# apollo4b register map
Vendor: Ambiq Micro; Series: Apollo; File version: 1.0
CPU: CM4 r1p0, little endian, MPU, FPU, I-cache, D-cache, VTOR, ITCM, DTCM, 3 interrupt priority bits, 0 interrupts
Registers are 32-bit, read-write, reset 0x0 unless marked. A register's access mark holds for its fields unless they carry their own. Offsets are from the block's base; [hi:lo] are bit positions; {n}, {i} and the like mark numbered series; 'fields as' and 'values as' point back to an identical list.

## MCUCTRL — MCU Miscellaneous Control Logic
Base 0x40020000
0x00 CHIPPN reset 0x8320098 — Chip Information
  [31:0] PARTNUM — BCD part number.
    0x8000000=APOLLO4 (Apollo4 part number is 0x08xxxxxx.); 0x7000000=APOLLO3P (Apollo3P part number is 0x07xxxxxx.); 0x6000000=APOLLO3 (Apollo3 part number is 0x06xxxxxx.); 0x3000000=APOLLO2 (Apollo2 part number is 0x03xxxxxx.); 0x1000000=APOLLO (Apollo part number is 0x01xxxxxx.); 0xFF000000=PN_M (Mask for the part number field.); 24=PN_S (Bit position for the part number field.); 0xF00000=MRAMSIZE_M (Mask for the MRAM_SIZE field. Values: 0: 0.5MB 1: 1.0MB 2: 1.5MB 3: 2.0MB); 20=MRAMSIZE_S (Bit position for the MRAM_SIZE field.); 0xF0000=SRAMSIZE_M (Mask for the SRAM_SIZE field. Values: 0: 384KB+512KB 1: 384KB+1MB 2: 384KB+1MB+384KB+96KB); 16=SRAMSIZE_S (Bit position for the SRAM_SIZE field.); 0xFF00=REV_M (Mask for the revision field. Bits [15:12] are major rev, [11:8] are minor rev. Values: 0: Major Rev A, Minor Rev 0 1: Major Rev B, Minor Rev 1); 8=REV_S (Bit position for the revision field.); 192=PKG_M (Mask for the package field. Values: 0: SIP 1: QFN 2: BGA 3: CSP); 6=PKG_S (Bit position for the package field.); 56=PINS_M (Mask for the pins field. Values: 0: 25 pins 1: 49 pins 2: 64 pins 3: 81 pins); 3=PINS_S (Bit position for the pins field.); 1=TEMP_S (Bit position for the temperature field.)
0x04 CHIPID0 — Unique Chip ID 0
  [31:0] CHIPID0 — Unique chip ID 0.
0x08 CHIPID1 — Unique Chip ID 1
  [31:0] CHIPID1 — Unique chip ID 1.
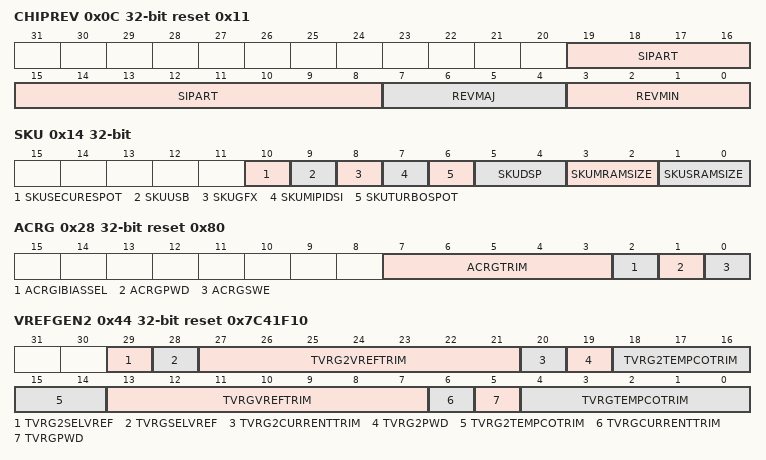
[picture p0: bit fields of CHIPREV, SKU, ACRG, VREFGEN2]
0x0C CHIPREV reset 0x11 — Chip Revision
  [19:8] SIPART — Silicon Part ID
  [7:4] REVMAJ — Major Revision ID.
    2=B (Apollo4 revision B); 1=A (Apollo4 revision A)
  [3:0] REVMIN — Minor Revision ID.
    3=REV2 (Apollo4 minor rev 2.); 2=REV1 (Apollo4 minor rev 1.); 1=REV0 (Apollo4 minor rev 0. Minor revision value, succeeding minor revisions will increment from this value.)
0x10 VENDORID — Unique Vendor ID
  [31:0] VENDORID
    0x414D4251=AMBIQ (Ambiq Vendor ID 'AMBQ')
0x14 SKU — Unique Chip SKU
  [10] SKUSECURESPOT — Secure boot feature
  [9] SKUUSB — USB available
  [8] SKUGFX — GFX available
  [7] SKUMIPIDSI — MIPI DSI available
  [6] SKUTURBOSPOT — High performance mode for MCU and DSPs.
  [5:4] SKUDSP — DSP availability SKU setting. 0:No DSPs available, 1: DSP0 only available, 2 (or 3): Both DSP0 and DSP1 are available
  [3:2] SKUMRAMSIZE — MRAM size SKU. 0:0.5MB, 1=1MB, 2=1.5MB, 3:2MB
  [1:0] SKUSRAMSIZE — SRAM SKU dictates the available memory for MCU. All of the MCU TCM is always available in addition to these. 0: 512K SSRAM, 1: 1MB SSRAM, 2: 1MB SSRAM + DSP Memories
0x20 DEBUGGER — Debugger Control
  [31:0] LOCKOUT — Lockout of debugger (SWD).
0x28 ACRG reset 0x80 — Active Current Reference Generator Control
  [7:3] ACRGTRIM — ACRG Trim value
  [2] ACRGIBIASSEL — Set the ACRG ibias. Note: the SWE mux select in PWRSEQ2SWE must be set for this to take effect. The inversion of this register is driven to analog.
    0=BGSEL (Selects the bandgap); 1=CCRGSEL (Selects the CCRG)
  [1] ACRGPWD — Power down the ACRG.
    1=ACRG_PWR_DN (Powers down the ACRG trim.)
  [0] ACRGSWE — Software enablement for ACRG register. A value of 1 will allow writes to the register
0x44 VREFGEN2 reset 0x7C41F10 — Voltage Reference Generator 2 Control
  [29] TVRG2SELVREF
  [28] TVRGSELVREF
  [27:21] TVRG2VREFTRIM — Calibrated voltage reference 580m trim
  [20] TVRG2CURRENTTRIM — Calibrated voltage reference current trim.
  [19] TVRG2PWD — Power Down, Calibrated Voltage Reference Generator.
    1=PWR_DN (Powers down the CVRG.)
  [18:14] TVRG2TEMPCOTRIM — Calibrated Voltage Reference Generator tc trim (bottom transistor)
  [13:7] TVRGVREFTRIM — Calibrated voltage reference 580m trim
  [6] TVRGCURRENTTRIM — Calibrated voltage reference current trim.
  [5] TVRGPWD — Power Down, Calibrated Voltage Reference Generator.
    1=PWR_DN (Powers down the CVRG.)
  [4:0] TVRGTEMPCOTRIM — Calibrated Voltage Reference Generator tc trim (bottom transistor)
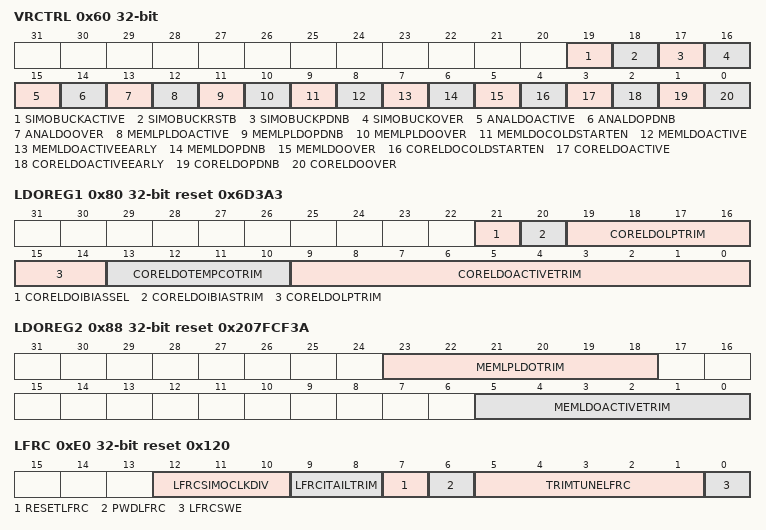
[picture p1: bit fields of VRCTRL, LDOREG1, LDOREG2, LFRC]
0x60 VRCTRL — Overrides for Voltage Regulators Controls
  [19] SIMOBUCKACTIVE — SIMO BUCK ACTIVE control. Override for PWRCTRL going to analog when SIMOBUCKOVER = 1
  [18] SIMOBUCKRSTB — SIMO BUCK RSTB control. Override for PWRCTRL going to analog when SIMOBUCKOVER = 1
  [17] SIMOBUCKPDNB — SIMO BUCK PDNB control. Override for PWRCTRL going to analog when SIMOBUCKOVER = 1
  [16] SIMOBUCKOVER — Override control for SIMO BUCK signals
  [15] ANALDOACTIVE — ANALDO LDO ACTIVE control. Override for PWRCTRL going to analog when ANALDOOVER = 1
  [14] ANALDOPDNB — ANALDO PDNB control. Override for PWRCTRL going to analog when ANALDOOVER = 1
  [13] ANALDOOVER — Override control for ANALDO signals
  [12] MEMLPLDOACTIVE — MEM LP LDO ACTVIVE control. Override for PWRCTRL going to analog when MEMLPLDOOVER = 1
  [11] MEMLPLDOPDNB — MEM LP LDO PDNB control. Override for PWRCTRL going to analog when MEMLPLDOOVER = 1
  [10] MEMLPLDOOVER — Override control for MEM LP LDO signals
  [9] MEMLDOCOLDSTARTEN — MEM LDO COLDSTART EN control. This is a shadow backed register and no need to set MEMLDOOVER.
  [8] MEMLDOACTIVE — MEM LDO ACTIVE control. Override for PWRCTRL going to analog when MEMLDOOVER = 1
  [7] MEMLDOACTIVEEARLY — MEM LDO EARLY ACTIVE control. Override for PWRCTRL going to analog when MEMLDOOVER = 1
  [6] MEMLDOPDNB — MEM LDO PDNB control. Override signal for PWRCTRL going to analog when MEMLDOOVER = 1
  [5] MEMLDOOVER — Override control for MEM LDO signals
  [4] CORELDOCOLDSTARTEN — CORE LDO COLDSTART EN control. This is a shadow backed register and no need to set CORELDOOVER.
  [3] CORELDOACTIVE — CORE LDO ACTIVE control. Override for PWRCTRL going to analog when CORELDOOVER = 1
  [2] CORELDOACTIVEEARLY — CORE LDO EARLY ACTIVE control. Override for PWRCTRL going to analog when CORELDOOVER = 1
  [1] CORELDOPDNB — CORE LDO PDNB control. Override for PWRCTRL going to analog when CORELDOOVER = 1
  [0] CORELDOOVER — Override control for CORE LDO signals
0x80 LDOREG1 reset 0x6D3A3 — CORELDO trims Reg
  [21] CORELDOIBIASSEL — Core LDO IBIAS sel. Note: the SWE mux select in PWRSEQ2SWE must be set for this to take effect.
  [20] CORELDOIBIASTRIM
  [19:14] CORELDOLPTRIM — CORE LDO Low Power Trim
  [13:10] CORELDOTEMPCOTRIM
  [9:0] CORELDOACTIVETRIM
0x88 LDOREG2 reset 0x207FCF3A — MEMLDO and MEMLPLDO Trims
  [23:18] MEMLPLDOTRIM, [5:0] MEMLDOACTIVETRIM
0xC4 HFRC2 — HFRC2 Control
  [21:11] HF2TUNE — Default HFRC2 frequency tune value
0xE0 LFRC reset 0x120 — LFRC Control
  [12:10] LFRCSIMOCLKDIV — SIMOBUCK LP mode clock divider
    0=DIV1 (Divide by 1); 1=DIV2 (Divide by 2); 2=DIV4 (Divide by 4); 3=DIV8 (Divide by 8); 4=DIV16 (Divide by 16); 5=DIV32 (Divide by 32)
  [9:8] LFRCITAILTRIM
  [7] RESETLFRC — LFRC Reset.
    0=EN (Enable LFRC.); 1=RESET (Reset LFRC.)
  [6] PWDLFRC — Power Down LFRC.
    0=PWRUP (Power up LFRC.); 1=PWRDN (Power down LFRC.)
  [5:1] TRIMTUNELFRC — LFRC Frequency Tune trim bits
  [0] LFRCSWE — LFRC Software Override Enable.
    0=OVERRIDE_DIS (LFRC Software Override Disable.); 1=OVERRIDE_EN (LFRC Software Override Enable.)
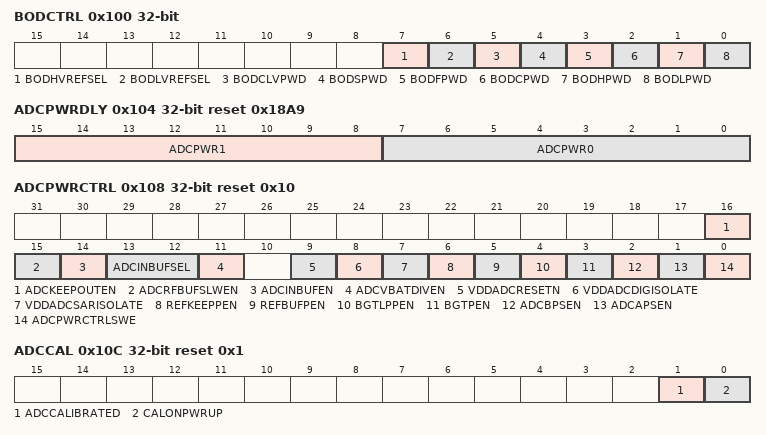
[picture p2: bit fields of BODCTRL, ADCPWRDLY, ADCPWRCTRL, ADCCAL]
0x100 BODCTRL — BOD control
  [7] BODHVREFSEL — BODH External Reference Select. Note: the SWE mux select in PWRSEQ2SWE must be set for this to take effect.
  [6] BODLVREFSEL — BODL External Reference Select. Note: the SWE mux select in PWRSEQ2SWE must be set for this to take effect.
  [5] BODCLVPWD — BODC_LV Power Down.
  [4] BODSPWD — BODS Power Down.
  [3] BODFPWD — BODF Power Down.
  [2] BODCPWD — BODC Power Down.
  [1] BODHPWD — BODH Power Down.
  [0] BODLPWD — BODL Power Down.
0x104 ADCPWRDLY reset 0x18A9 — ADC Power Up Delay Control
  [15:8] ADCPWR1 — Delay time for ADC Reference Buffer settling time in 64x ADC clock increments. Delay = 64*ADCPWR1*ADC_CLK
  [7:0] ADCPWR0 — Additional delay time for ADC Reference Buffer settling time in 64x ADC clock increments. Delay = 64*ADCPWR0*ADC_CLK.
0x108 ADCPWRCTRL reset 0x10 — ADC Power Control
  [16] ADCKEEPOUTEN — ADC reference keeper out en
  [15] ADCRFBUFSLWEN — ADC reference buffer slew enable
  [14] ADCINBUFEN — ADC Input Buffer Power Enable ( if the ADCPWRCTRLSWE bit is set )
  [13:12] ADCINBUFSEL — ADC input buffer mux select
  [11] ADCVBATDIVEN — ADC VBAT DIV Power Enable ( if the ADCPWRCTRLSWE bit is set )
  [9] VDDADCRESETN — RESETN signal for Power Switched SAR and Digital Controller (when global power switch is off and if the ADCPWRCTRLSWE bit is set)
    0=ASSERT (Resetn is asserted); 1=DEASSERT (Resetn is de-asserted)
  [8] VDDADCDIGISOLATE — ISOLATE signal for ADC Digital Contoller ( when ADCAPSEN is switched off and if the ADCPWRCTRLSWE bit is set)
    0=DIS (No Isolation); 1=EN (Isolate)
  [7] VDDADCSARISOLATE — ISOLATE signal for Power Switched SAR ( when ADCBPSEN is switched off )
    0=DIS (No Isolation); 1=EN (Isolate)
  [6] REFKEEPPEN — Reference Buffer Keeper Power Switch Enable
    0=DIS (Reference Buffer Keeper Power Switch disable.); 1=EN (Reference Buffer Keeper Power Switch enable.)
  [5] REFBUFPEN — Reference Buffer Power Switch Enable
    0=DIS (Reference Buffer Power Switch disable.); 1=EN (Reference Buffer Power Switch enable.)
  [4] BGTLPPEN — Bandgap and Temperature Sensor Power Switch Enable
    0=DIS (Bandgap and temperature sensor disable.); 1=EN (Bandgap and temperature sensor enable.)
  [3] BGTPEN — Bandgap and Temperature Sensor Power Switch Enable
    values as BGTLPPEN
  [2] ADCBPSEN — Enable the Analog, IO and SAR Digital logic Power Switch on when set to 1 if the ADCPWRCTRLSWE bit is set.
    0=DIS (ADC power switch software power disable.); 1=EN (ADC power switch software power enable.)
  [1] ADCAPSEN — Enable the Global ADC Power Switch on when set to 1 if the ADCPWRCTRLSWE bit is set.
    values as ADCBPSEN
  [0] ADCPWRCTRLSWE — ADC Power Control Software Override Enable
    0=OVERRIDE_DIS (ADC temperature sensor and bandgap Software Override Disable.); 1=OVERRIDE_EN (ADC temperature sensor and bandgap Software Override Enable.)
0x10C ADCCAL reset 0x1 — ADC Calibration Control
  [1] ADCCALIBRATED — Status for ADC Calibration
    0=FALSE (ADC is not calibrated); 1=TRUE (ADC is calibrated)
  [0] CALONPWRUP — Run ADC Calibration on initial power up sequence
    0=DIS (Disable automatic calibration on initial power up); 1=EN (Enable automatic calibration on initial power up)
0x110 ADCBATTLOAD — ADC Battery Load Enable
  [0] BATTLOAD — Enable the ADC battery load resistor
    0=DIS (Battery load is disconnected); 1=EN (Battery load is enabled)
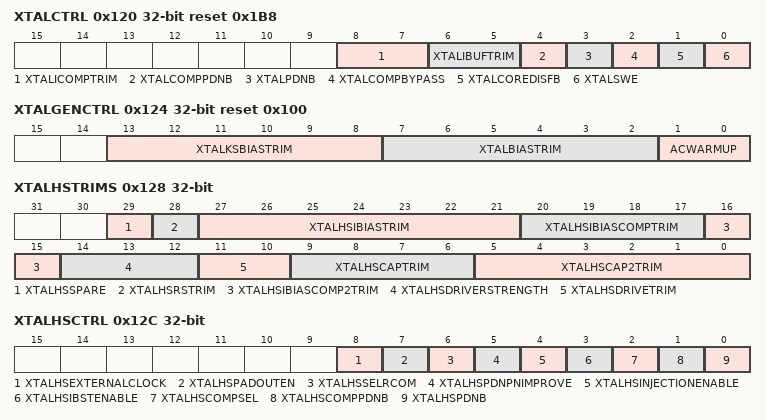
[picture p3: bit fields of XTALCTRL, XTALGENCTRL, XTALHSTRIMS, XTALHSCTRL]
0x120 XTALCTRL reset 0x1B8 — XTAL Oscillator Control
  [8:7] XTALICOMPTRIM
  [6:5] XTALIBUFTRIM — XTAL IBUFF trim
  [4] XTALCOMPPDNB — XTAL Oscillator Power Down Comparator.
    1=PWRUPCOMP (Power up XTAL oscillator comparator.); 0=PWRDNCOMP (Power down XTAL oscillator comparator.)
  [3] XTALPDNB — XTAL Oscillator Power Down Core.
    1=PWRUPCORE (Power up XTAL oscillator core.); 0=PWRDNCORE (Power down XTAL oscillator core.)
  [2] XTALCOMPBYPASS — XTAL Oscillator Bypass Comparator.
    0=USECOMP (Use the XTAL oscillator comparator.); 1=BYPCOMP (Bypass the XTAL oscillator comparator.)
  [1] XTALCOREDISFB — XTAL Oscillator Disable Feedback.
    0=EN (Enable XTAL oscillator comparator.); 1=DIS (Disable XTAL oscillator comparator.)
  [0] XTALSWE — XTAL Software Override Enable.
    0=OVERRIDE_DIS (XTAL Software Override Disable.); 1=OVERRIDE_EN (XTAL Software Override Enable.)
0x124 XTALGENCTRL reset 0x100 — XTAL Oscillator General Control
  [13:8] XTALKSBIASTRIM — XTAL IBIAS Kick start trim. This trim value is used during the startup process to enable a faster lock.
  [7:2] XTALBIASTRIM
  [1:0] ACWARMUP — Auto-calibration delay control
    0=SEC1 (Warmup period of 1-2 seconds); 1=SEC2 (Warmup period of 2-4 seconds); 2=SEC4 (Warmup period of 4-8 seconds); 3=SEC8 (Warmup period of 8-16 seconds)
0x128 XTALHSTRIMS
  [29] XTALHSSPARE, [28] XTALHSRSTRIM, [27:21] XTALHSIBIASTRIM, [20:17] XTALHSIBIASCOMPTRIM, [16:15] XTALHSIBIASCOMP2TRIM, [14:12] XTALHSDRIVERSTRENGTH, [11:10] XTALHSDRIVETRIM, [9:6] XTALHSCAPTRIM, [5:0] XTALHSCAP2TRIM
0x12C XTALHSCTRL — XTALHS Control
  [8] XTALHSEXTERNALCLOCK, [7] XTALHSPADOUTEN, [6] XTALHSSELRCOM, [5] XTALHSPDNPNIMPROVE, [4] XTALHSINJECTIONENABLE, [3] XTALHSIBSTENABLE, [2] XTALHSCOMPSEL, [1] XTALHSCOMPPDNB, [0] XTALHSPDNB
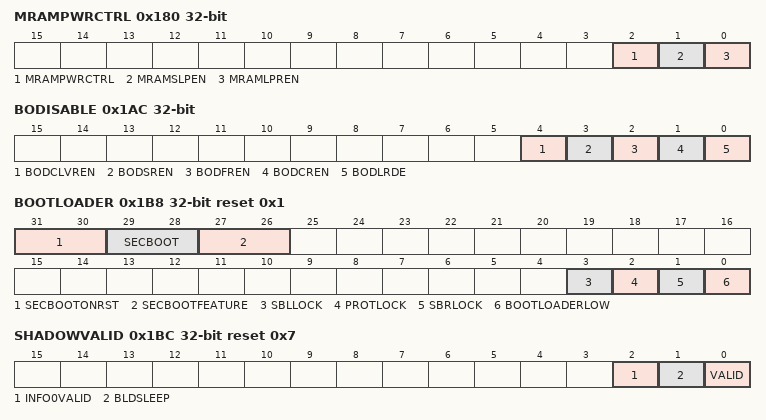
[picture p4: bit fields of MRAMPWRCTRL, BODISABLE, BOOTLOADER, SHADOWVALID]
0x180 MRAMPWRCTRL — MRAM Power Control
  [2] MRAMPWRCTRL — MRAM low power mode control. '0' tmc_lpr and tmc_slp are driven into mcu_ctrl, '1' tmc_lpr and tmc_slp are driven into MRAM wrapper.
  [1] MRAMSLPEN — MRAM sleep mode enable
  [0] MRAMLPREN — MRAM low power mode enable
0x1AC BODISABLE — Brownout Disable
  [4] BODCLVREN — Disable VDDC_LV Brown Out reset.
    1=EN (Enable VDDC_LV Brown Out reset.); 0=DIS (Disable VDDC_LV Brown Out reset.)
  [3] BODSREN — Disable VDDS Brown Out reset.
    1=EN (Enable VDDS Brown Out reset.); 0=DIS (Disable VDDS Brown Out reset.)
  [2] BODFREN — Disable VDDF Brown Out reset.
    1=EN (Enable VDDF Brown Out reset.); 0=DIS (Disable VDDF Brown Out reset.)
  [1] BODCREN — Disable VDDC Brown Out reset.
    1=EN (Enable VDDC Brown Out reset.); 0=DIS (Disable VDDC Brown Out reset.)
  [0] BODLRDE — Disable Unregulated 1.8V Brown-out reset.
    0=EN (Enable Unregulated 1.8v brown out reset.); 1=DIS (Disable Unregulated 1.8v brown out reset.)
0x1B8 BOOTLOADER reset 0x1 — Bootloader and secure boot functions
  [31:30] SECBOOTONRST — Indicates whether the secure boot on warm reset is enabled
    0=DISABLED (Secure boot disabled); 1=ENABLED (Secure boot enabled); 2=ERROR (Error in secure boot configuration)
  [29:28] SECBOOT — Indicates whether the secure boot on cold reset is enabled
    values as SECBOOTONRST
  [27:26] SECBOOTFEATURE — Indicates whether the secure boot feature is enabled.
    values as SECBOOTONRST
  [3] SBLLOCK — Secure boot loader lock. Always resets to 1, write 1 to clear. Enables system visibility to bootloader until set.
    1=LOCK (Enable the secure boot lock)
  [2] PROTLOCK — This field controls access to OEM keybank and restricts further application of NVM protections via the FLASHWPROTn and FLASHRPROTn registers. On read, 0 indicates locked, 1 indicates unlocked. Write 1 to clear the field (assert the lock). Default value of the hardware is 1 (unlocked), but the default value is also affected by INFOC_SECURITY->PLONEXIT. If PLONEXIT is set, PROTLOCK is asserted by SBL and the OEM application will see the value as 0 (locked).
    1=LOCK (On write, this value asserts the lock. On read, see above description.); 0=DEFAULT (On write, this value (writing 0) has no effect. On read, see above description.)
  [1] SBRLOCK — Secure boot ROM lock. Always resets to 1, write 1 to clear. Enables system visibility to bootloader until set.
    1=LOCK (Enable the secure boot lock)
  [0] BOOTLOADERLOW — Determines whether the bootloader code is visible at address 0x00000000 or not. Resets to 1, write 1 to clear.
    1=ADDR0 (Bootloader code at 0x00000000.)
0x1BC SHADOWVALID reset 0x7 — Register to indicate whether the shadow registers have been successfully loaded from the Flash Information Space.
  [2] INFO0VALID — Indicates whether info0 contains valid data
    1=VALID (Flash info0 (customer) space contains valid data.)
  [1] BLDSLEEP — Indicates whether the bootloader should sleep or deep sleep if no image loaded.
    1=DEEPSLEEP (Bootloader will go to deep sleep if no flash image loaded)
  [0] VALID — Indicates whether the shadow registers contain valid data from the Flash Information Space.
    1=VALID (Flash information space contains valid data.)
0x1C0 SCRATCH0 — Scratch register that is not reset by any reset
  [0] HALTREQ — Reset-Halt requested from debugger.
0x200 DBGR1 reset 0x12345678 — Read-only debug 1
  [31:0] ONETO8 — Read-only register for communication validation
0x204 DBGR2 reset 0xC001C0DE — Read-only debug 2
  [31:0] COOLCODE — Read-only register for communication validation
0x220 PMUENABLE reset 0x1 — Control bit to enable/disable the PMU
  [0] ENABLE — PMU Enable Control bit. When set, the MCU's PMU will place the MCU into the lowest power consuming Deep Sleep mode upon execution of a WFI instruction (dependent on the setting of the SLEEPDEEP bit in the ARM SCR register). When cleared, regardless of the requested sleep mode, the PMU will not enter the lowest power Deep Sleep mode, instead entering the Sleep mode.
    0=DIS (Disable MCU power management.); 1=EN (Enable MCU power management.)
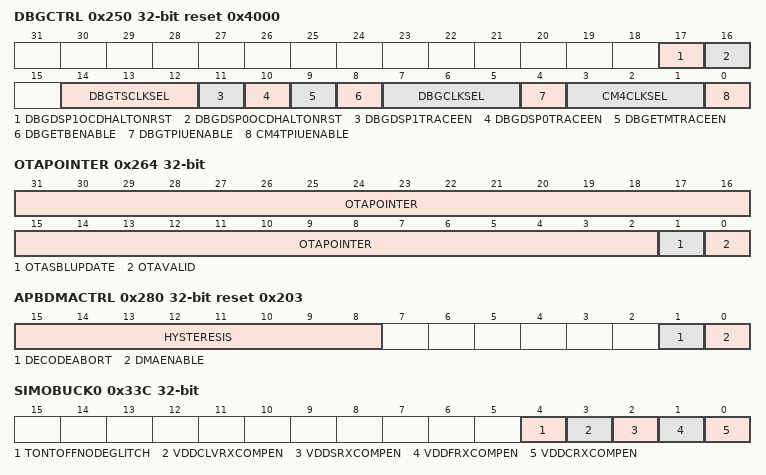
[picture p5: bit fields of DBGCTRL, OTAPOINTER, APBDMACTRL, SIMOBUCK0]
0x250 DBGCTRL reset 0x4000 — Debug subsystem Control. Determines the debug components enable and clk frequency.
  [17] DBGDSP1OCDHALTONRST — Debug subsystem DSP1 OCD Halt on Reset
    0=DIS (Disable DSP1 OCD Halt on Reset.); 1=EN (Enable DSP1 OCD Halt on Reset.)
  [16] DBGDSP0OCDHALTONRST — Debug subsystem DSP0 OCD Halt on Reset
    0=DIS (Disable DSP0 OCD Halt on Reset.); 1=EN (Enable DSP0 OCD Halt on Reset.)
  [14:12] DBGTSCLKSEL — This field selects the frequency of the ARM M4 dbg ts port.
    0=LOWPWR (Low power state.); 1=HFRCDIV2 (Selects HFRC divided by 2 as the source dbg ts clk); 2=HFRCDIV8 (Selects HFRC divided by 8 as the source dbg ts clk); 3=HFRCDIV16 (Selects HFRC divided by 16 as the source dbg ts clk); 4=HFRCDIV32 (Selects HFRC divided by 32 as the source dbg ts clk)
  [11] DBGDSP1TRACEEN — Debug subsystem DSP1 trace enable
    0=DIS (Disable DSP1 trace.); 1=EN (Enable DSP1 trace.)
  [10] DBGDSP0TRACEEN — Debug subsystem DSP0 trace enable
    0=DIS (Disable DSP0 trace.); 1=EN (Enable DSP0 trace.)
  [9] DBGETMTRACEEN — Debug subsystem ETM trace enable
    0=DIS (Disable ETM trace.); 1=EN (Enable ETM trace.)
  [8] DBGETBENABLE — Debug subsystem ETB enable to store the trace data.
    0=DIS (Disable ETB.); 1=EN (Enable ETB.)
  [7:5] DBGCLKSEL — This field selects the frequency of the Debug Trace TPIU port.
    0=LOWPWR (Low power state.); 1=HFRC96 (Selects HFRC 96Mhz as the source TPIU clk); 2=HFRC48 (Selects HFRC 48Mhz as the source TPIU clk); 3=HFRC24 (Selects HFRC 24Mhz as the source TPIU clk); 4=HFRC6 (Selects HFRC 6Mhz as the source TPIU clk); 5=HFRC3 (Selects HFRC 3Mhz as the source TPIU clk); 6=HFRC1_5 (Selects HFRC 1.5Mhz as the source TPIU clk)
  [4] DBGTPIUENABLE — TPIU Enable field. When set, the Debug Trace TPIU is enabled and data can be streamed out of the MCU ETM or DSP TRAXs.
    0=DIS (Disable the TPIU.); 1=EN (Enable the TPIU.)
  [3:1] CM4CLKSEL — This field selects the frequency of the ARM M4 TPIU port.
    0=LOWPWR (Low power state.); 1=HFRCDIV4 (Selects HFRC divided by 4 as the source TPIU clk (24 MHz).); 2=HFRCDIV16 (Selects HFRC divided by 16 as the source TPIU clk (6 MHz).); 3=HFRCDIV32 (Selects HFRC divided by 32 as the source TPIU clk (3 MHz).); 4=HFRCDIV64 (Selects HFRC divided by 64 as the source TPIU clk (1.5 MHz).)
  [0] CM4TPIUENABLE — TPIU Enable field. When set, the ARM M4 TPIU is enabled and data can be streamed out of the MCU's SWO port using the ARM ITM and TPIU modules.
    0=DIS (Disable the TPIU.); 1=EN (Enable the TPIU.)
0x264 OTAPOINTER — OTA (Over the Air) Update Pointer/Status. Reset only by POA
  [31:2] OTAPOINTER — Flash page pointer with updated OTA image
  [1] OTASBLUPDATE — Indicates that the sbl_init has been updated
  [0] OTAVALID — Indicates that an OTA update is valid
0x280 APBDMACTRL reset 0x203 — DMA Control Register. Determines misc settings for DMA operation
  [15:8] HYSTERESIS — This field determines how long the DMA engine of apb/disp/gfx will remain active during deep sleep before shutting down and returning the system to full deep sleep. Values are based on a 94KHz clock and are roughly 10us increments for a range of ~10us to 2.55ms
  [1] DECODEABORT — APB Decode Abort. When set, the APB bridge will issue a data abort (bus fault) on transactions to peripherals that are powered down. When set to 0, writes are quietly discarded and reads return 0.
    0=DISABLE (Bus operations to powered down peripherals are quietly discarded); 1=ENABLE (Bus operations to powered down peripherals result in a bus fault.)
  [0] DMAENABLE — Enable the DMA controller. When disabled, DMA requests will be ignored by the controller
    0=DISABLE (DMA operations disabled); 1=ENABLE (DMA operations enabled)
0x338 KEXTCLKSEL — Locks the state of the EXTCLKSEL register from writes. This is done to prevent errant writes to the register, as this could cause the chip to halt. Write a value of 0x53 to unlock write access to the EXTCLKSEL register. Once unlocked, the register will read back a 1 to undicate this is unlocked. Writing the register with any other value other than 0x53 will enable the lock.
  [31:0] KEXTCLKSEL — Key register value.
    83=Key (Key value to unlock the register.)
0x33C SIMOBUCK0 — This WRITE_ONLY register controls various buck parameters. It will read back as 0x00000000.
  [4] TONTOFFNODEGLITCH — Enable the ton and toff signals no deglitch output.
  [3] VDDCLVRXCOMPEN — Enable the VDDC LV rail.
  [2] VDDSRXCOMPEN — Enable the VDDS rail.
  [1] VDDFRXCOMPEN — Enable the VDDS rail.
  [0] VDDCRXCOMPEN — Enable the VDDC rail.
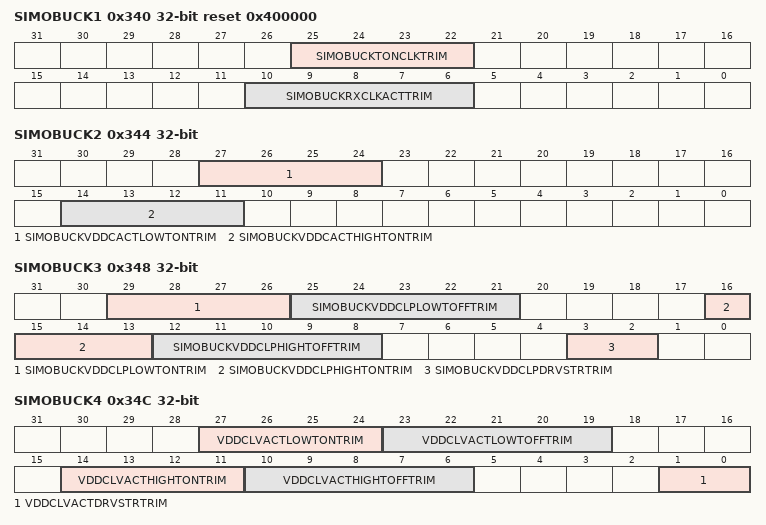
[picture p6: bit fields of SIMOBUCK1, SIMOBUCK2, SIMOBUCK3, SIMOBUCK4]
0x340 SIMOBUCK1 reset 0x400000 — 1. Control the even division of 3 clocks: refresh, low power and TONCLK. 2. Control gap bewteen secondary switches. 3. Debug features: control the amount of time TONCLK is on, and the time before snubber asserts for each buck sequence. 4. Enable or disable the observation bus. 5. Select the buck sequence operation mode. 6. Control delay between primary Pmos and Nmos transitions.
  [25:22] SIMOBUCKTONCLKTRIM — This divides the 100 MHz ton clock. Even divides are supported only. This value represents the division amount minus 1.
  [10:6] SIMOBUCKRXCLKACTTRIM — This divides the 5 MHz refresh clock. Even divides are supported only. This value represents the division amount minus 1.
0x344 SIMOBUCK2 — SIMO Buck Muxed VDDC Active Sequence Trim Control
  [27:24] SIMOBUCKVDDCACTLOWTONTRIM — VDDC active high ton trim control for Buck sequence.
  [14:11] SIMOBUCKVDDCACTHIGHTONTRIM — VDDC active high ton trim control for Buck sequence.
0x348 SIMOBUCK3 — SIMO Buck Muxed VDDC low power Sequence Trim Control
  [29:26] SIMOBUCKVDDCLPLOWTONTRIM — VDDC LP low ton trim control for Buck sequence.
  [25:21] SIMOBUCKVDDCLPLOWTOFFTRIM — VDDC LP low toff trim control for Buck sequence.
  [16:13] SIMOBUCKVDDCLPHIGHTONTRIM — VDDC LP high ton trim control for Buck sequence.
  [12:8] SIMOBUCKVDDCLPHIGHTOFFTRIM — VDDC LP high toff trim control for Buck sequence.
  [3:2] SIMOBUCKVDDCLPDRVSTRTRIM — VDDC LP trim control for drive strength.
0x34C SIMOBUCK4 — SIMO Buck Muxed VDDC LV Active Sequence Trim Control
  [27:24] VDDCLVACTLOWTONTRIM — VDDC LV active low ton trim control for Buck sequence.
  [23:19] VDDCLVACTLOWTOFFTRIM — VDDC LV active low trim control for a 500 MHz clock inside the simobuck analog design.
  [14:11] VDDCLVACTHIGHTONTRIM — VDDC LV active high ton trim control for Buck sequence.
  [10:6] VDDCLVACTHIGHTOFFTRIM — VDDC LV active high toff trim control for Buck sequence.
  [1:0] VDDCLVACTDRVSTRTRIM — VDDC LV active trim control for drive strength.
0x354 SIMOBUCK6 — SIMO Buck Muxed VDDF Active Sequence Trim Control
  [20:17] SIMOBUCKVDDFACTHIGHTONTRIM — VDDF active high ton trim control for Buck sequence.
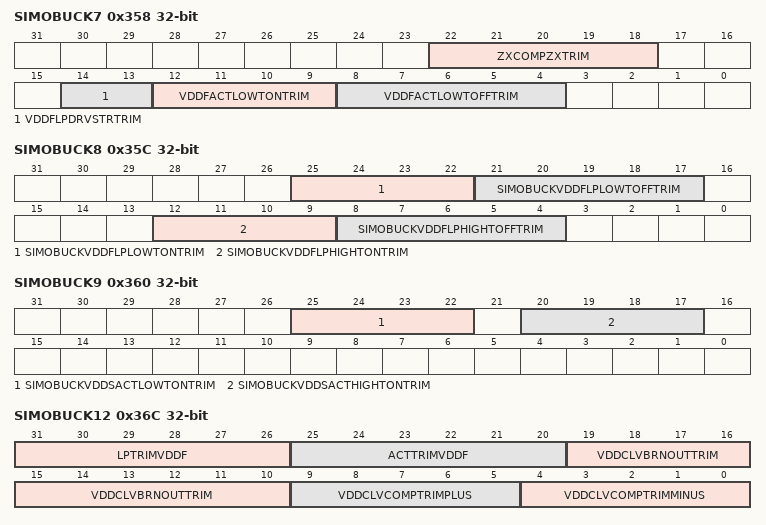
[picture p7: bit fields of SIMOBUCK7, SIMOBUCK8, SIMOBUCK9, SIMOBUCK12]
0x358 SIMOBUCK7 — SIMO Buck Muxed VDDF active Sequence Trim Control
  [22:18] ZXCOMPZXTRIM — Zxcomp trim. Feedthrough to analog.
  [14:13] VDDFLPDRVSTRTRIM — VDDF active trim control for drive strength.
  [12:9] VDDFACTLOWTONTRIM — VDDF active low ton trim control for Buck sequence.
  [8:4] VDDFACTLOWTOFFTRIM — VDDF active low toff trim control for Buck sequence.
0x35C SIMOBUCK8 — SIMO Buck Muxed VDDF Low Power Sequence Trim Control
  [25:22] SIMOBUCKVDDFLPLOWTONTRIM — VDDF low power low ton trim control for Buck sequence.
  [21:17] SIMOBUCKVDDFLPLOWTOFFTRIM — VDDF low power low toff trim control for Buck sequence.
  [12:9] SIMOBUCKVDDFLPHIGHTONTRIM — VDDF low power high ton trim control for Buck sequence.
  [8:4] SIMOBUCKVDDFLPHIGHTOFFTRIM — VDDF low power high toff trim control for Buck sequence.
0x360 SIMOBUCK9 — SIMO Buck Muxed VDDS Active Sequence Trim Control
  [25:22] SIMOBUCKVDDSACTLOWTONTRIM — VDDS active low ton trim control for Buck sequence.
  [20:17] SIMOBUCKVDDSACTHIGHTONTRIM — VDDS active high ton trim control for Buck sequence.
0x36C SIMOBUCK12 — SIMO Buck Compare, Brown out, Active, Low power Trim Control
  [31:26] LPTRIMVDDF — Low power VDDF trim.
  [25:20] ACTTRIMVDDF — Active VDDF trim.
  [19:10] VDDCLVBRNOUTTRIM — Digital brown out max counter value for VDDC LV rail.
  [9:5] VDDCLVCOMPTRIMPLUS — Static trim to allow separation when low power GT active rail.
  [4:0] VDDCLVCOMPTRIMMINUS — Static trim to allow separation between low power and active rail.
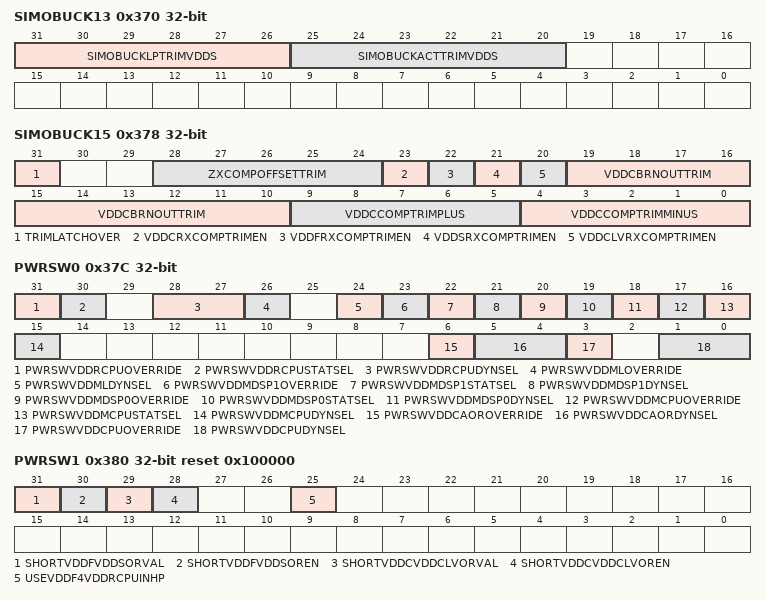
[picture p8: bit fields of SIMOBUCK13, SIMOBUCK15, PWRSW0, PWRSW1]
0x370 SIMOBUCK13 — SIMO Buck Compare, Brown out, Active, Low power Trim Control
  [31:26] SIMOBUCKLPTRIMVDDS — Low power VDDS trim.
  [25:20] SIMOBUCKACTTRIMVDDS — Active VDDS trim.
0x378 SIMOBUCK15 — SIMO Buck Compare, Brown out, Active and Low power Trim Control
  [31] TRIMLATCHOVER — Override / Bypass the simobuck trim latch to enable on-the-fly trimming for VDDF and VDDS active and LP trims
  [28:24] ZXCOMPOFFSETTRIM — Zxcomp offset trim. Feedthrough to analog.
  [23] VDDCRXCOMPTRIMEN — Enable the VDDC rail. If not enabled, the rail will not be regulated. This must be done before simobuck comes up.
  [22] VDDFRXCOMPTRIMEN — Enable the VDDF rail. If not enabled, the rail will not be regulated. This must be done before simobuck comes up.
  [21] VDDSRXCOMPTRIMEN — Enable the VDDS rail. If not enabled, the rail will not be regulated. This must be done before simobuck comes up.
  [20] VDDCLVRXCOMPTRIMEN — Enable the VDDC LV rail. If not enabled, the rail will not be regulated. This must be done before simobuck comes up.
  [19:10] VDDCBRNOUTTRIM — Digital brown out max counter value for VDDC rail.
  [9:5] VDDCCOMPTRIMPLUS — Static trim to allow separation when low power GT active rail.
  [4:0] VDDCCOMPTRIMMINUS — Static trim to allow separation between low power and active rail.
0x37C PWRSW0 — PWRSW Control 0
  [31] PWRSWVDDRCPUOVERRIDE — override enable for pwrsw_vddrcpu_dynsel and pgn
  [30] PWRSWVDDRCPUSTATSEL — VDDRCPU power switch static select
    1=VDDC (Select VDDC rail); 0=VDDFLP (Select VDDFLP rail)
  [28:27] PWRSWVDDRCPUDYNSEL — override value for pwrsw_vddrcpu_dynsel
  [26] PWRSWVDDMLOVERRIDE — override enable for pwrsw_vddml_dynsel
  [24] PWRSWVDDMLDYNSEL — override value for pwrsw_vddml_dynsel
  [23] PWRSWVDDMDSP1OVERRIDE — override enable for pwrsw_vddmdsp1_dynsel
  [22] PWRSWVDDMDSP1STATSEL — VDDMDSP1 power switch static select
    0=VDDC (Select VDDC rail); 1=VDDF (Select VDDF rail)
  [21] PWRSWVDDMDSP1DYNSEL — override value for pwrsw_vddmdsp1_dynsel
  [20] PWRSWVDDMDSP0OVERRIDE — override enable for pwrsw_vddmdsp0_dynsel
  [19] PWRSWVDDMDSP0STATSEL — VDDMDSP0 power switch static select
    0=VDDC (Select VDDC rail); 1=VDDF (Select VDDF rail)
  [18] PWRSWVDDMDSP0DYNSEL — override value for pwrsw_vddmdsp0_dynsel
  [17] PWRSWVDDMCPUOVERRIDE — override enable for pwrsw_vddmcpu_dynsel
  [16] PWRSWVDDMCPUSTATSEL — VDDMCPU power switch static select
    0=VDDC (Select VDDC rail); 1=VDDF (Select VDDF rail)
  [15] PWRSWVDDMCPUDYNSEL — override value for pwrsw_vddmcpu_dynsel
  [6] PWRSWVDDCAOROVERRIDE — override enable for pwrsw_vddcaor_dynsel
  [5:4] PWRSWVDDCAORDYNSEL — override value for pwrsw_vddcaor_dynsel
  [3] PWRSWVDDCPUOVERRIDE — override enable for pwrsw_vddcpu_dynsel and pgn
  [1:0] PWRSWVDDCPUDYNSEL — override value for pwrsw_vddcpu_dynsel
0x380 PWRSW1 reset 0x100000 — PWRSW Control 1
  [31] SHORTVDDFVDDSORVAL — pwrsw short override value for vddf/vdds
  [30] SHORTVDDFVDDSOREN — pwrsw short override select for vddf/vdds
  [29] SHORTVDDCVDDCLVORVAL — pwrsw short override value for vddc/vddclv
  [28] SHORTVDDCVDDCLVOREN — pwrsw short override select for vddc/vddclv
  [25] USEVDDF4VDDRCPUINHP — Setting this bit selects VDDF for VDDRCPU in when MCU is in HP mode. This is valid for only normal operational mode (i.e without overrides).
{0x3A8+4i} FLASHWPROT{i} (i=0..3) — These bits write-protect flash in 16KB chunks.
  [31:0] FW{i}BITS — Write protect flash {0x0+0x80000*i} - {0x7FFFF+0x80000*i}. Each bit provides write protection for 16KB chunks of flash data space. Bits are cleared by writing a 1 to the bit. When read, 0 indicates the region is protected. Bits are sticky (can be set when PROTLOCK is 1, but only cleared by reset)
{0x3B8+4i} FLASHRPROT{i} (i=0..3) — These bits read-protect flash in 16KB chunks.
  [31:0] FR{i}BITS — Copy (read) protect flash {0x0+0x80000*i} - {0x7FFFF+0x80000*i}. Each bit provides read protection for 16KB chunks of flash. Bits are cleared by writing a 1 to the bit. When read, 0 indicates the region is protected. Bits are sticky (can be set when PROTLOCK is 1, but only cleared by reset)
0x3C8 DMASRAMWPROT0 — These bits write-protect system SRAM from DMA operations in 8KB chunks.
  [31:0] DMAWPROT0 — Write protect SRAM from DMA. Each bit provides write protection for an 8KB region of memory. When set to 1, the region will be protected from DMA writes, when set to 0, DMA may write the region.
0x3CC DMASRAMWPROT1 — These bits write-protect system SRAM from DMA operations in 8KB chunks.
  [15:0] DMAWPROT1 — Write protect SRAM from DMA. Each bit provides write protection for an 8KB region of memory. When set to 1, the region will be protected from DMA writes, when set to 0, DMA may write the region.
0x3D0 DMASRAMRPROT0 — These bits read-protect system SRAM from DMA operations in 8KB chunks.
  [31:0] DMARPROT0 — Read protect SRAM from DMA. Each bit provides write protection for an 8KB region of memory. When set to 1, the region will be protected from DMA reads, when set to 0, DMA may read the region.
0x3D4 DMASRAMRPROT1 — These bits read-protect system SRAM from DMA operations in 8KB chunks.
  [15:0] DMARPROT1 — Read protect SRAM from DMA. Each bit provides write protection for an 8KB region of memory. When set to 1, the region will be protected from DMA reads, when set to 0, DMA may read the region.
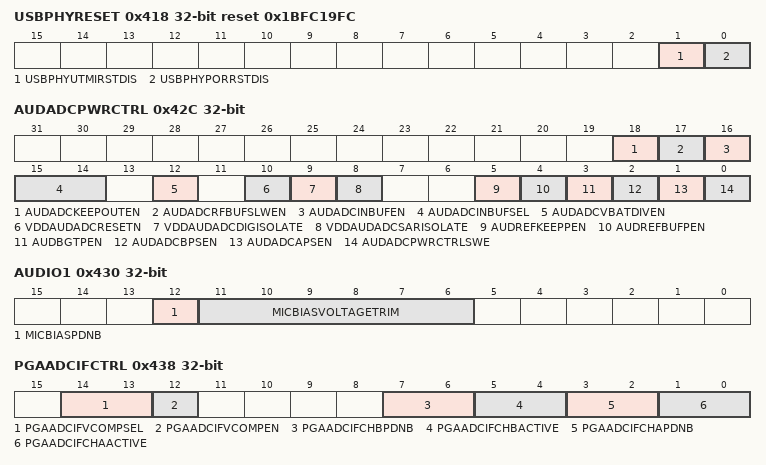
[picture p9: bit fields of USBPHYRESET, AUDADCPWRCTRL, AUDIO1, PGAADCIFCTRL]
0x418 USBPHYRESET reset 0x1BFC19FC — DSP0 CACHE RAM TRIM
  [1] USBPHYUTMIRSTDIS — De-assert USB PHY UTMI reset override
  [0] USBPHYPORRSTDIS — De-assert USB PHY POR reset override
0x42C AUDADCPWRCTRL — Audio ADC Power Control
  [18] AUDADCKEEPOUTEN — Audio ADC reference keeper out en
  [17] AUDADCRFBUFSLWEN — Audio ADC reference buffer slew enable
  [16] AUDADCINBUFEN — Audio ADC Input Buffer Power Enable ( if the AUDADCPWRCTRLSWE bit is set )
  [15:14] AUDADCINBUFSEL — Audio ADC input buffer mux select
  [12] AUDADCVBATDIVEN — Audio ADC VBAT DIV Power Enable ( if the AUDADCPWRCTRLSWE bit is set )
  [10] VDDAUDADCRESETN — RESETN signal for Power Switched SAR and Digital Controller (when global power switch is off and if the AUDADCPWRCTRLSWE bit is set)
    values as ADCPWRCTRL.VDDADCRESETN
  [9] VDDAUDADCDIGISOLATE — ISOLATE signal for audio ADC Digital Contoller ( when AUDADCAPSEN is switched off and if the AUDADCPWRCTRLSWE bit is set)
    0=DIS (No Isolation); 1=EN (Isolate)
  [8] VDDAUDADCSARISOLATE — ISOLATE signal for Power Switched SAR ( when AUDADCBPSEN is switched off )
    0=DIS (No Isolation); 1=EN (Isolate)
  [5] AUDREFKEEPPEN — Reference Buffer Keeper Power Switch Enable
    values as ADCPWRCTRL.REFKEEPPEN
  [4] AUDREFBUFPEN — Reference Buffer Power Switch Enable
    values as ADCPWRCTRL.REFBUFPEN
  [3] AUDBGTPEN — Bandgap and Temperature Sensor Power Switch Enable
    values as ADCPWRCTRL.BGTLPPEN
  [2] AUDADCBPSEN — Enable the Analog, IO and SAR Digital logic Power Switch on when set to 1 if the AUDADCPWRCTRLSWE bit is set.
    0=DIS (AUDADC power switch software power disable.); 1=EN (AUDADC power switch software power enable.)
  [1] AUDADCAPSEN — Enable the Global audio ADC Power Switch on when set to 1 if the AUDADCPWRCTRLSWE bit is set.
    values as AUDADCBPSEN
  [0] AUDADCPWRCTRLSWE — Audio ADC Power Control Software Override Enable
    0=OVERRIDE_DIS (Audio ADC temperature sensor and bandgap Software Override Disable.); 1=OVERRIDE_EN (Audio ADC temperature sensor and bandgap Software Override Enable.)
0x430 AUDIO1 — Audio trims 1
  [12] MICBIASPDNB — Power down control for the block
  [11:6] MICBIASVOLTAGETRIM — Output voltage trim
0x438 PGAADCIFCTRL — PGA ADCIF control
  [14:13] PGAADCIFVCOMPSEL — Select for VCOMP output (0: A0, 1: A1, 2: B0, 3: B1)
  [12] PGAADCIFVCOMPEN — Enable for VCOMP output
  [7:6] PGAADCIFCHBPDNB — Power down for channels B0 and B1 (0 = powered down; 1 = standby)
  [5:4] PGAADCIFCHBACTIVE — PGAADCIF active signal for channels B0 and B1. Starts and stops 2 clocks after demultiplexed SOC signal.
  [3:2] PGAADCIFCHAPDNB — Power down for channels A0 and A1 (0 = powered down; 1 = standby)
  [1:0] PGAADCIFCHAACTIVE — PGAADCIF active signal for channels A0 and A1. Starts and stops 2 clocks after demultiplexed SOC signal.
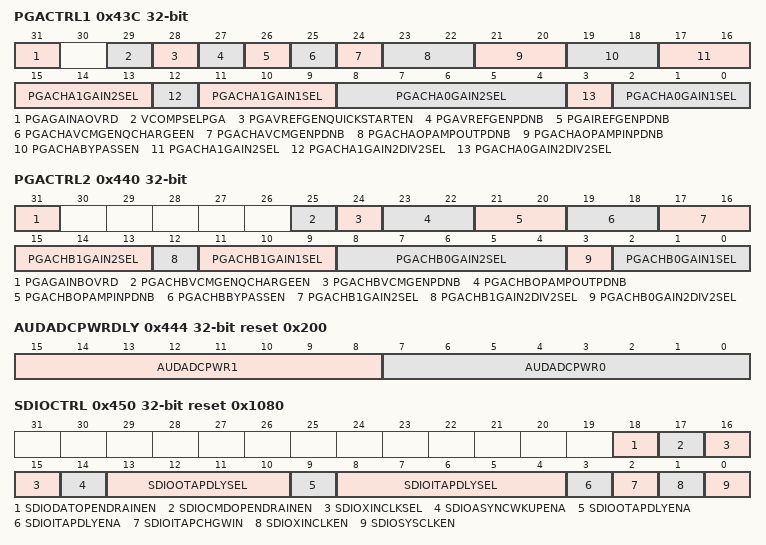
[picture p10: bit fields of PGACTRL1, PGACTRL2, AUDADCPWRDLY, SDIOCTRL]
0x43C PGACTRL1 — PGA control 1
  [31] PGAGAINAOVRD — Apply BYPASS and GAIN bits from this register (for channel A) instead of automatically via audio ADC. Note that audio ADC FIFO meta data will not reflect dB gain as used when configuring audio ADC.
  [29] VCOMPSELPGA — Select for VCOMP output (0: A0, 1: A1, 2: B0, 3: B1)
  [28] PGAVREFGENQUICKSTARTEN — VREFGEN quick start enable (pulsed during startup)
  [27] PGAVREFGENPDNB — VREFGEN power down (0: powered down, 1: powered up)
  [26] PGAIREFGENPDNB — IREFGEN power down (0: powered down, 1: powered up)
  [25] PGACHAVCMGENQCHARGEEN — Channel A VCMGEN quick charge enable (pulsed during channel powerup)
  [24] PGACHAVCMGENPDNB — Channel A VCMGEN power down (0: powered down, 1: powered up)
  [23:22] PGACHAOPAMPOUTPDNB — Channels A0 and A1 output stage opamp power down (0: powered down, 1: powered up)
  [21:20] PGACHAOPAMPINPDNB — Channels A0 and A1 input stage opamp power down (0: powered down, 1: powered up). Must be 1 when respective PGACHABYPASSEN = 0.
  [19:18] PGACHABYPASSEN — Bypass enable for Channels A0 and A1 (1: bypass, when gain LT 12 dB; 0: otherwise)
  [17:13] PGACHA1GAIN2SEL — Channel A1 PGA gain (0: 0dB, ..., 23: 11.5dB in 0.5 dB steps)
  [12] PGACHA1GAIN2DIV2SEL — Channel A1 PGA divide by two select (0: 0 dB, 1: -6dB), needed for fully differential inputs
  [11:9] PGACHA1GAIN1SEL — Channel A1 preamp gain (0: 12dB, ..., 7: 33dB in 3 dB steps)
  [8:4] PGACHA0GAIN2SEL — Channel A0 PGA gain (0: 0dB, ..., 23: 11.5dB in 0.5 dB steps)
  [3] PGACHA0GAIN2DIV2SEL — Channel A0 PGA divide by two select (0: 0 dB, 1: -6dB), needed for fully differential inputs
  [2:0] PGACHA0GAIN1SEL — Channel A0 preamp gain (0: 12dB, ..., 7: 33dB in 3 dB steps)
0x440 PGACTRL2 — PGA control 2
  [31] PGAGAINBOVRD — Apply BYPASS and GAIN bits from this register (for channel B) instead of automatically via audio ADC. Note that audio ADC FIFO meta data will not reflect dB gain as used when configuring audio ADC.
  [25] PGACHBVCMGENQCHARGEEN — Channel B VCMGEN quick charge enable (pulsed during channel powerup)
  [24] PGACHBVCMGENPDNB — Channel B VCMGEN power down (0: powered down, 1: powered up)
  [23:22] PGACHBOPAMPOUTPDNB — Channels B0 and B1 output stage opamp power down (0: powered down, 1: powered up)
  [21:20] PGACHBOPAMPINPDNB — Channels B0 and B1 input stage opamp power down (0: powered down, 1: powered up). Must be 1 when respective PGACHBBYPASSEN = 0.
  [19:18] PGACHBBYPASSEN — Bypass enable for Channels B0 and B1 (1: bypass, when gain LT 12 dB; 0: otherwise)
  [17:13] PGACHB1GAIN2SEL — Channel B1 PGA gain (0: 0dB, ..., 23: 11.5dB in 0.5 dB steps)
  [12] PGACHB1GAIN2DIV2SEL — Channel B1 PGA divide by two select (0: 0 dB, 1: -6dB), needed for fully differential inputs
  [11:9] PGACHB1GAIN1SEL — Channel B1 preamp gain (0: 12dB, ..., 7: 33dB in 3 dB steps)
  [8:4] PGACHB0GAIN2SEL — Channel B0 PGA gain (0: 0dB, ..., 23: 11.5dB in 0.5 dB steps)
  [3] PGACHB0GAIN2DIV2SEL — Channel B0 PGA divide by two select (0: 0 dB, 1: -6dB), needed for fully differential inputs
  [2:0] PGACHB0GAIN1SEL — Channel B0 preamp gain (0: 12dB, ..., 7: 33dB in 3 dB steps)
0x444 AUDADCPWRDLY reset 0x200 — Audio ADC Power Up Delay Control
  [15:8] AUDADCPWR1 — ADC Reference Keeper enable delay in 16 ADC CLK increments for ADC_CLKSEL = 0x1, 8 ADC CLOCK increments for ADC_CLKSEL = 0x2.
  [7:0] AUDADCPWR0 — ADC Reference Buffer Power Enable delay in 64 ADC CLK increments for ADC_CLKSEL = 0x1, 32 ADC CLOCK increments for ADC_CLKSEL = 0x2.
0x450 SDIOCTRL reset 0x1080 — SDIO/eMMC Control
  [18] SDIODATOPENDRAINEN — SDIO DAT line configured as open-drian. 0: Push-pull mode, 1: Open-drain mode
  [17] SDIOCMDOPENDRAINEN — SDIO CMD line configured as open-drian. 0: Push-pull mode, 1: Open-drain mode
  [16:15] SDIOXINCLKSEL — Select clock source for SDIO xin_clk.
  [14] SDIOASYNCWKUPENA — SDIO asynchronous wakeup mode. 0: Synchronous wakeup mode, 1: Asynchronous wakeup mode
  [13:10] SDIOOTAPDLYSEL — Selects one of the 16 Taps on the sdcard_clk. This is effective only when otapdlyena is asserted.
  [9] SDIOOTAPDLYENA — Used to enable the selective Tap delay on the sdcard_clk so as to generate the delayed sdcard_clk. This is used to latch the CMD/DAT outputs to generate delay on them w.r.t CLK going out. This signal along with otapdlysel[3:0] selects the amount of delay to be inserted on the Clock line. This signal should not be asserted when operating in DS mode.
  [8:4] SDIOITAPDLYSEL — Selects one of the 32 Taps on the rxclk_in line. This is effective only when itapdlyena is asserted and Tuning is not enabled.
  [3] SDIOITAPDLYENA — Used to enable selective Tap delay line on the Looped back SD Clock (rxclk_in). This signal along with the itapdlysel[4:0] selects the the amount of delay to be inserted on the line. When Tuning is enabled (for SDR104 and optionally for SDR50), this signal is ignored and internalcontrols are used instead. This should not be asserted when operating in DS mode.
  [2] SDIOITAPCHGWIN — This is used to gate the output of the Tap Delay lines so as to avoid glithches being propagated into the Core. This signal should be asserted few clocks before the itapdlysel changes and should be asserted for few clocks after.
  [1] SDIOXINCLKEN — SDIO serial clock source enable.
  [0] SDIOSYSCLKEN — SDIO system clock enable.
0x454 PDMCTRL reset 0x1 — PDM Control
  [0] PDMGLOBALEN — PDM global enable to allow all PDMs to have synchronized interface clocks and FIFO sampling.
